# LKS32MC03x register map
Vendor: Linko Ltd.; Series: LKS32MC03x; File version: 1.0
CPU: CM0 r1p0, little endian, MPU, no FPU, 3 interrupt priority bits
Registers are 32-bit, read-write, reset 0x0 unless marked. A register's access mark holds for its fields unless they carry their own. Offsets are from the block's base; [hi:lo] are bit positions; {n}, {i} and the like mark numbered series.

## MCPWM — MCPWM registers
Base 0x40010700
0x00 TH00 — CH0 P 16-bit Threshold Value
  [15:0] TH00 — Channel0 P-side threshold
0x04 TH01 — CH0 N 16-bit Threshold Value
  [15:0] TH01 — Channel0 N-side threshold
0x08 TH10 — CH1 P 16-bit Threshold Value
  [15:0] TH10 — Channel1 P-side threshold
0x0C TH11 — CH1 N 16-bit Threshold Value
  [15:0] TH11 — Channel1 N-side threshold
0x10 TH20 — CH2 P 16-bit Threshold Value
  [15:0] TH20 — Channel2 P-side threshold
0x14 TH21 — CH2 N 16-bit Threshold Value
  [15:0] TH21 — Channel2 N-side threshold
0x18 TH30 — CH3 P 16-bit Threshold Value
  [15:0] TH30 — Channel3 P-side threshold
0x1C TH31 — CH3 N 16-bit Threshold Value
  [15:0] TH31 — Channel3 N-side threshold
{0x20+4i} TMR{i} reset 0x7FFF (i=0..3) — ADC Trigger time {i}
  [15:0] TMR{i} — ADC Trigger time {i} counter value
0x30 TH0 — Base Counter 0 15-bit Unsigned Threshold Value
  [14:0] TH0 — MCPWM Counter 0 TH
0x34 TH1 — Base Counter 1 15-bit Unsigned Threshold Value
  [14:0] TH1 — MCPWM Counter 1 TH
0x38 CNT0 — Base 0 Counter 16-bit Signed Threshold Value
  [15:0] CNT0 — MCPWM Counter 0 Value
0x3C CNT1 — Base 1 Counter 16-bit Signed Value
  [15:0] CNT1 — MCPWM Counter 1 Value
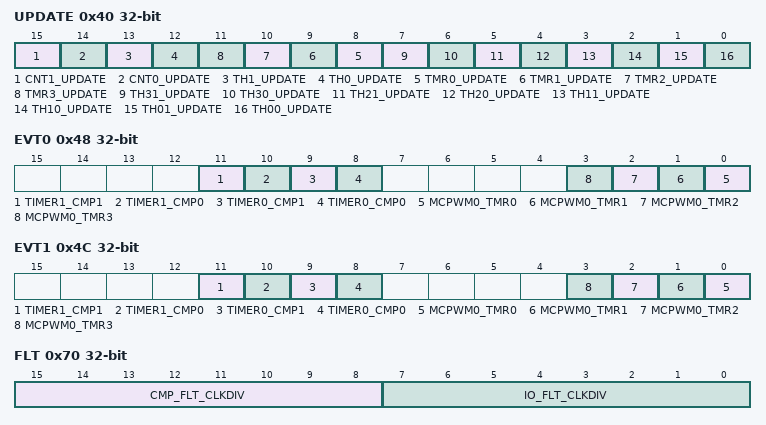
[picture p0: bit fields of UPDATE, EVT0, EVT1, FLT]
0x40 UPDATE wo (reset mask 0x1FFF) — Mask Registers Manual Reload Configuration
  [15] CNT1_UPDATE — Write 1 to Trig CNT1 Update Forcely
  [14] CNT0_UPDATE — Write 1 to Trig CNT0 Update Forcely
  [13] TH1_UPDATE — Write 1 to Trig TH1 Update Forcely
  [12] TH0_UPDATE — Write 1 to Trig TH0 Update Forcely
  [n+8] TMR{n}_UPDATE (n=0..3) — Write 1 to Trig TMR{n} Update Forcely
  [7] TH31_UPDATE — Write 1 to Trig TH31 Update Forcely
  [6] TH30_UPDATE — Write 1 to Trig TH30 Update Forcely
  [5] TH21_UPDATE — Write 1 to Trig TH21 Update Forcely
  [4] TH20_UPDATE — Write 1 to Trig TH20 Update Forcely
  [3] TH11_UPDATE — Write 1 to Trig TH11 Update Forcely
  [2] TH10_UPDATE — Write 1 to Trig TH10 Update Forcely
  [1] TH01_UPDATE — Write 1 to Trig TH01 Update Forcely
  [0] TH00_UPDATE — Write 1 to Trig TH00 Update Forcely
0x44 FCNT — If MCPWM_FAIL012[15] = 1, when fail0/1 occure, store MCPWM_CNT0 to MCPWM_FCNT. If MCPWM_FAIL3[15] = 1, when fail2/3 occure, store MCPWM_CNT0 to MCPWM_FCNT.
  [15:0] FCNT — Counter Value when failure event happens
0x48 EVT0 — MCPWM Base 0 External Trigger Register
  [11] TIMER1_CMP1 — TIMER1 CMP1 base 0 Trigger
  [10] TIMER1_CMP0 — TIMER1 CMP0 base 0 Trigger
  [9] TIMER0_CMP1 — TIMER0 CMP1 base 0 Trigger
  [8] TIMER0_CMP0 — TIMER0 CMP0 base 0 Trigger
  [n] MCPWM0_TMR{n} (n=0..3) — MCPWM0 TMR{n} base 0 Trigger
0x4C EVT1 — MCPWM Base 1 External Trigger Register
  [11] TIMER1_CMP1 — TIMER1 CMP1 base 1 Trigger
  [10] TIMER1_CMP0 — TIMER1 CMP0 base 1 Trigger
  [9] TIMER0_CMP1 — TIMER0 CMP1 base 1 Trigger
  [8] TIMER0_CMP0 — TIMER0 CMP0 base 1 Trigger
  [n] MCPWM0_TMR{n} (n=0..3) — MCPWM0 TMR{n} base 1 Trigger
0x50 DTH0 (reset mask 0xFFFF) — Channelx N Dead Zone Control Register, 10-bit Unsigned
0x54 DTH1 (reset mask 0xFFFF) — Channelx P Dead Zone Control Register, 10-bit Unsigned
0x70 FLT — FAIL signal filter config
  [15:8] CMP_FLT_CLKDIV — Clock Source is System Clock, Divide Range is 1 to 256
  [7:0] IO_FLT_CLKDIV — Clock Source is System Clock, Divide Range is 1 to 256
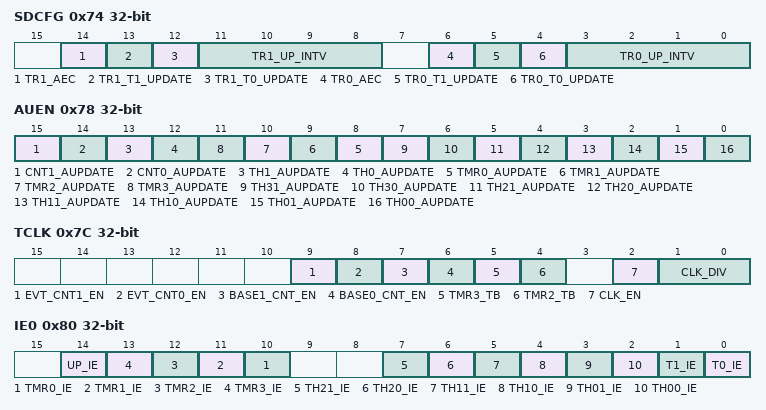
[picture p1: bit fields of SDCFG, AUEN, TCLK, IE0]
0x74 SDCFG — Shadow Registers Reload Configuration
  [14] TR1_AEC — Set MCPWM_FAIL3.MOE upon update events or not
  [13] TR1_T1_UPDATE — Update counter1 based shadow registers @ T1 event
  [12] TR1_T0_UPDATE — Update counter1 based shadow registers @ T0 event
  [11:8] TR1_UP_INTV — Counter1 based Shadow Register Auto Update Interval
  [6] TR0_AEC — Set MCPWM_FAIL012.MOE upon update events or not
  [5] TR0_T1_UPDATE — Update counter0 based shadow registers @ T1 event
  [4] TR0_T0_UPDATE — Update counter0 based shadow registers @ T0 event
  [3:0] TR0_UP_INTV — Counter0 based Shadow Register Auto Update Interval
0x78 AUEN — Auto update enable
  [15] CNT1_AUPDATE — MCPWM_CNT1 auto update enable
  [14] CNT0_AUPDATE — MCPWM_CNT0 auto update enable
  [13] TH1_AUPDATE — MCPWM_TH1 auto update enable
  [12] TH0_AUPDATE — MCPWM_TH0 auto update enable
  [n+8] TMR{n}_AUPDATE (n=0..3) — MCPWM_TMR{n} auto update enable
  [7] TH31_AUPDATE — MCPWM_TH31 auto update enable
  [6] TH30_AUPDATE — MCPWM_TH30 auto update enable
  [5] TH21_AUPDATE — MCPWM_TH21 auto update enable
  [4] TH20_AUPDATE — MCPWM_TH20 auto update enable
  [3] TH11_AUPDATE — MCPWM_TH11 auto update enable
  [2] TH10_AUPDATE — MCPWM_TH10 auto update enable
  [1] TH01_AUPDATE — MCPWM_TH01 auto update enable
  [0] TH00_AUPDATE — MCPWM_TH00 auto update enable
0x7C TCLK — MCPWM Clock Configuration Register
  [9] EVT_CNT1_EN — Base Counter1 external trigger enable
  [8] EVT_CNT0_EN — Base Counter0 external trigger enable
  [7] BASE1_CNT_EN — Base Counter1 Enable
  [6] BASE0_CNT_EN — Base Counter0 Enable
  [5] TMR3_TB — TMR3 base counter select
    0=CNT0 (Base Counter0); 1=CNT1 (Base Counter1)
  [4] TMR2_TB — TMR2 base counter select
    0=CNT0 (Base Counter0); 1=CNT1 (Base Counter1)
  [2] CLK_EN — Module Clock Enable or Not
  [1:0] CLK_DIV — Module Clock Divider Setting, Clock Source is System Clock
    0=DIV1 (Main clock is not divided); 1=DIV2 (Main clock is divided by 2); 2=DIV4 (Main clock is divided by 4); 3=DIV8 (Main clock is divided by 8)
0x80 IE0 — Counter0 based Interrupt Sources Enable
  [14] UP_IE — Shade Register Update Interrupt Enable
  [n+10] TMR{n}_IE (n=0..3) — Counter0 is equal to TMR{n} Interrupt Enable
  [7] TH21_IE — Counter0 is equal to TH21 Interrupt Enable
  [6] TH20_IE — Counter0 is equal to TH20 Interrupt Enable
  [5] TH11_IE — Counter0 is equal to TH11 Interrupt Enable
  [4] TH10_IE — Counter0 is equal to TH10 Interrupt Enable
  [3] TH01_IE — Counter0 is equal to TH01 Interrupt Enable
  [2] TH00_IE — Counter0 is equal to TH00 Interrupt Enable
  [1] T1_IE — Counter0 is equal to 0 Interrupt Enable
  [0] T0_IE — Counter0 Return to -TH Interrupt Enable
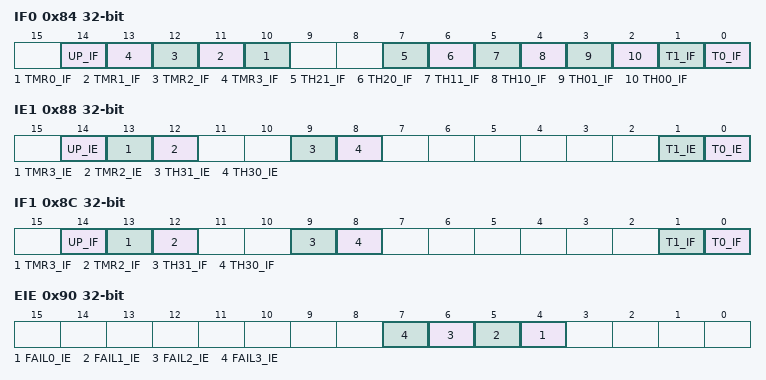
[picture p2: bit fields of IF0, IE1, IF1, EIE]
0x84 IF0 — Counter0 based Interrupt Flags
  [14] UP_IF — Shade Register Update Interrupt Flag
  [n+10] TMR{n}_IF (n=0..3) — TMR{n} Interrupt Flag,Counter0 is equal to TMR{n}
  [7] TH21_IF — TH21 Interrupt Flag,Counter0 is equal to TH21
  [6] TH20_IF — TH20 Interrupt Flag,Counter0 is equal to TH20
  [5] TH11_IF — TH11 Interrupt Flag,Counter0 is equal to TH11
  [4] TH10_IF — TH10 Interrupt Flag,Counter0 is equal to TH10
  [3] TH01_IF — TH01 Interrupt Flag,Counter0 is equal to TH01
  [2] TH00_IF — TH00 Interrupt Flag,Counter0 is equal to TH00
  [1] T1_IF — T1 Interrupt Flag,Counter0 Return to -TH
  [0] T0_IF — T0 Interrupt Flag,Counter0 Return to -TH
0x88 IE1 — Counter1 based Interrupt Sources Enable
  [14] UP_IE — Shade Register Update Interrupt Enable
  [13] TMR3_IE — Counter1 is equal to TMR3 Interrupt Enable
  [12] TMR2_IE — Counter1 is equal to TMR2 Interrupt Enable
  [9] TH31_IE — Counter1 is equal to TH31 Interrupt Enable
  [8] TH30_IE — Counter1 is equal to TH30 Interrupt Enable
  [1] T1_IE — Counter1 is equal to 0 Interrupt Enable
  [0] T0_IE — Counter1 Return to -TH Interrupt Enable
0x8C IF1 — Counter1 based Interrupt Flags
  [14] UP_IF — Shade Register Update Interrupt Flag
  [13] TMR3_IF — TMR3 Interrupt Flag,Counter1 is equal to TMR3
  [12] TMR2_IF — TMR2 Interrupt Flag,Counter1 is equal to TMR2
  [9] TH31_IF — TH31 Interrupt Flag,Counter1 is equal to TH31
  [8] TH30_IF — TH30 Interrupt Flag,Counter1 is equal to TH30
  [1] T1_IF — T1 Interrupt Flag,Counter1 Return to -TH
  [0] T0_IF — T0 Interrupt Flag,Counter1 Return to -TH
0x90 EIE — Error Interrupt Sources Enable
  [n+4] FAIL{n}_IE (n=0..3) — FAIL{n} Interrupt
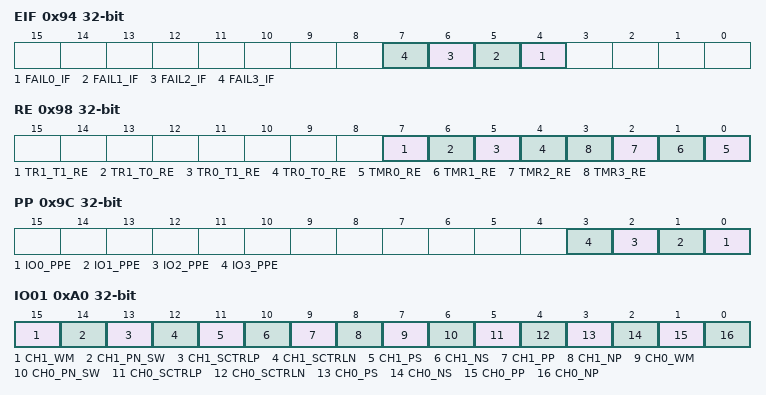
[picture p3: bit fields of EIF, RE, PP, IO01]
0x94 EIF — Error Interrupt Flags
  [n+4] FAIL{n}_IF (n=0..3) — FAIL{n} Interrupt Flag
0x98 RE (reset mask 0x3F) — DMA request enable
  [7] TR1_T1_RE — Counter1 Crossing Zero Event DMA request enable
  [6] TR1_T0_RE — Counter1 Start Over Event DMA request enable
  [5] TR0_T1_RE — Counter0 Crossing Zero Event DMA request enable
  [4] TR0_T0_RE — Counter0 Start Over Event DMA request enable
  [n] TMR{n}_RE (n=0..3) — ADC trigger {n} DMA request enable
0x9C PP — Push-Pull configuration
  [n] IO{n}_PPE (n=0..3) — IO{n} Push-Pull mode enable
0xA0 IO01 — Channel 0/1 Setting
  [15] CH1_WM — Channel_1 WorkMode
  [14] CH1_PN_SW — Channel_1 P/N Switch
  [13] CH1_SCTRLP — Channel_1 SoftCtrlP
  [12] CH1_SCTRLN — Channel_1 SoftCtrlN
  [11] CH1_PS — Channel_1 P Source
  [10] CH1_NS — Channel_1 N Source
  [9] CH1_PP — Channel_1 P Polarity
  [8] CH1_NP — Channel_1 N Polarity
  [7] CH0_WM — Channel_0 WorkMode
  [6] CH0_PN_SW — Channel_0 P/N Switch
  [5] CH0_SCTRLP — Channel_0 SoftCtrlP
  [4] CH0_SCTRLN — Channel_0 SoftCtrlN
  [3] CH0_PS — Channel_0 P Source
  [2] CH0_NS — Channel_0 N Source
  [1] CH0_PP — Channel_0 P Polarity
  [0] CH0_NP — Channel_0 N Polarity
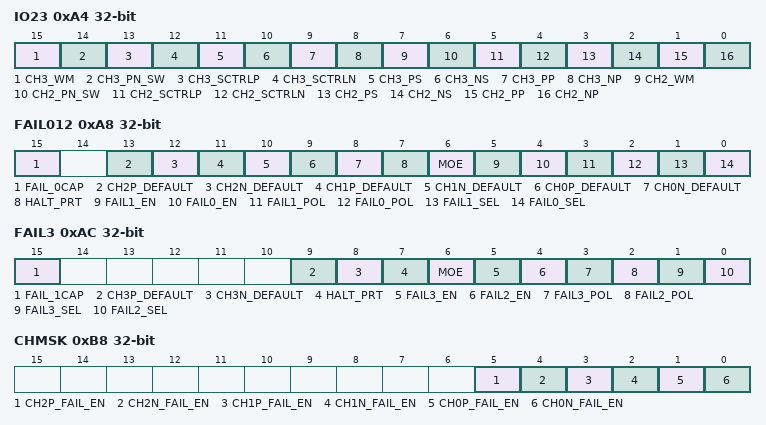
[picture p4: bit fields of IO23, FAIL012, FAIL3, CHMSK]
0xA4 IO23 — Channel 2/3 Setting
  [15] CH3_WM — Channel_3 WorkMode
  [14] CH3_PN_SW — Channel_3 P/N Switch
  [13] CH3_SCTRLP — Channel_3 SoftCtrlP
  [12] CH3_SCTRLN — Channel_3 SoftCtrlN
  [11] CH3_PS — Channel_3 P Source
  [10] CH3_NS — Channel_3 N Source
  [9] CH3_PP — Channel_3 P Polarity
  [8] CH3_NP — Channel_3 N Polarity
  [7] CH2_WM — Channel_2 WorkMode
  [6] CH2_PN_SW — Channel_2 P/N Switch
  [5] CH2_SCTRLP — Channel_2 SoftCtrlP
  [4] CH2_SCTRLN — Channel_2 SoftCtrlN
  [3] CH2_PS — Channel_2 P Source
  [2] CH2_NS — Channel_2 N Source
  [1] CH2_PP — Channel_2 P Polarity
  [0] CH2_NP — Channel_2 N Polarity
0xA8 FAIL012 — MCPWM Channel 012 Short Control Register
  [15] FAIL_0CAP — Save Counter0 to MCPWM_FCNT during fail0/1 event
  [13] CH2P_DEFAULT — CH2_P Default Value
  [12] CH2N_DEFAULT — CH2_N Default Value
  [11] CH1P_DEFAULT — CH1_P Default Value
  [10] CH1N_DEFAULT — CH1_N Default Value
  [9] CH0P_DEFAULT — CH0_P Default Value
  [8] CH0N_DEFAULT — CH0_N Default Value
  [7] HALT_PRT — MCU in Debug Mode(Halted by Debug), MCPWM Close or Not
  [6] MOE — MCPWM Output Enable
  [5] FAIL1_EN — FAIL 1 Short Protect Enable or Not
  [4] FAIL0_EN — FAIL 0 Short Protect Enable or Not
  [3] FAIL1_POL — FAIL 1 active polarity
  [2] FAIL0_POL — FAIL 0 active polarity
  [1] FAIL1_SEL — Select from CMP1 or IO 1
  [0] FAIL0_SEL — Select from CMP0 or IO 0
0xAC FAIL3 — MCPWM Channel 3 Short Control Register
  [15] FAIL_1CAP — Save Counter1 to MCPWM_FCNT during fail2/3 event
  [9] CH3P_DEFAULT — CH3_P Default Value
  [8] CH3N_DEFAULT — CH3_N Default Value
  [7] HALT_PRT — MCU in Debug Mode(Halted by Debug), MCPWM Close or Not
  [6] MOE — MCPWM Output Enable
  [5] FAIL3_EN — FAIL 3 Short Protect Enable or Not
  [4] FAIL2_EN — FAIL 2 Short Protect Enable or Not
  [3] FAIL3_POL — FAIL 3 active polarity
  [2] FAIL2_POL — FAIL 2 active polarity
  [1] FAIL3_SEL — Select from CMP1 or IO 1
  [0] FAIL2_SEL — Select from CMP0 or IO 0
0xB0 PRT wo — MCPWM Register Protection.Write 0xDEAD to unlock Protect
  [15:0] KEY
    0xDEAD=KEY (Unlock key)
0xB4 SWAP — MCPWM channel swap
  [7:0] SWAP
    0=DEFAULT (Default pin wiring); 103=SWAP (Swapped pin wiring)
0xB8 CHMSK — MCPWM channel mask
  [5] CH2P_FAIL_EN — Set ch2p to default during failure event
  [4] CH2N_FAIL_EN — Set ch2n to default during failure event
  [3] CH1P_FAIL_EN — Set ch1p to default during failure event
  [2] CH1N_FAIL_EN — Set ch1n to default during failure event
  [1] CH0P_FAIL_EN — Set ch0p to default during failure event
  [0] CH0N_FAIL_EN — Set ch0n to default during failure event
